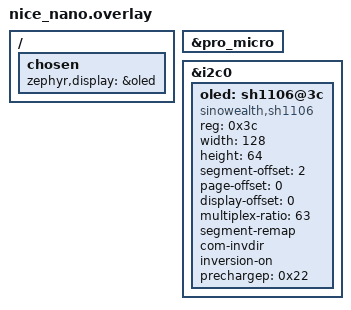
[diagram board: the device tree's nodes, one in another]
/* Alias xiao_d to pro_micro for old-workspace ZMK (board name: nice_nano). */
xiao_d: &pro_micro {};

/* Pinctrl for i2c0 (P0.17=SDA, P0.20=SCL) is already defined in the
 * board's nice_nano-pinctrl.dtsi; just enable i2c0 and attach the OLED. */
&i2c0 {
    status = "okay";
    oled: sh1106@3c {
        compatible = "sinowealth,sh1106";
        reg = <0x3c>;
        width = <128>;
        height = <64>;
        segment-offset = <2>;
        page-offset = <0>;
        display-offset = <0>;
        multiplex-ratio = <63>;
        segment-remap;
        com-invdir;
        inversion-on;
        prechargep = <0x22>;
    };
};

/ {
    chosen {
        zephyr,display = &oled;
    };
};
